# CY8C5888LTI_LP097 register map
File version: 0.1
CY8C58LP
Registers are 8-bit, read-write, no defined reset value unless marked. A register's access mark holds for its fields unless they carry their own. Offsets are from the block's base; lines under a group give offsets from that group; [hi:lo] are bit positions; {n}, {i} and the like mark numbered series; 'fields as' and 'values as' point back to an identical list; <NAME> marks a mode.

## Memory map
0x00000000 ADC_SAR_2 — SAR ADC
0x00000000 SPIS_1
0x00000000 Timer_1
0x00000000 ADC_SAR_1 — SAR ADC
0x00000000 UART_1 — UART

## ADC_SAR_2 — SAR ADC
Base 0x00000000
0x40004614 SAR_TR0 — SAR trim register
{0x40005900+i} SAR_CSR{i} (i=0..6) — SAR status and control register {i}
0x40005B20 SAR_SW0 — SAR Analog Routing Register 0
{0x40005B20+i} SAR_SW{i} (i=2..4) — SAR Analog Routing Register {i}
0x40005B26 SAR_SW6 — SAR Analog Routing Register 6
0x40005B27 SAR_CLK — SAR Clock Selection Register
0x40005BA0 SAR_WRK 16-bit — SAR working register

## SPIS_1
Base 0x00000000
0x4000640A SPIS_1_TX_DATA — SPIS TX Data
0x4000640A SPIS_1_RX_DATA — SPIS RX Data
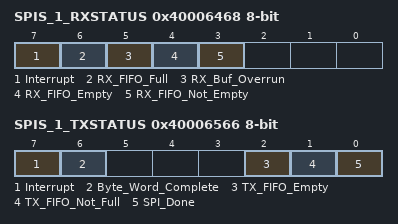
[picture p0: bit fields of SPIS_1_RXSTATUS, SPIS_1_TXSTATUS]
0x40006468 SPIS_1_RXSTATUS — SPIS RX Status Register
  [7] Interrupt ro — Set when interrupt occurs
  [6] RX_FIFO_Full ro — Set when the RX Data FIFO is full
  [5] RX_Buf_Overrun ro — Set when RX Data has overrun the 4 byte/word FIFO without being moved to the RX buffer cmemory array (if one exists)
  [4] RX_FIFO_Empty ro — Set when the RX Data FIFO is empty
  [3] RX_FIFO_Not_Empty ro — Set when the RX Data FIFO is not empty. That is, at least one byte/word is in the RX FIFO
0x40006566 SPIS_1_TXSTATUS — SPIS TX Status Register
  [7] Interrupt ro — Set when interrupt occurs
  [6] Byte_Word_Complete ro — Set when a byte/word transmit has completed
  [2] TX_FIFO_Empty ro — Set when the TX Data FIFO is empty
  [1] TX_FIFO_Not_Full ro — Set when the TX Data FIFO is not full
  [0] SPI_Done ro — Set when all of the data in the transmit FIFO has been sent. Set when Byte/Word Complete has been set and TX Data FIFO is empty

## Timer_1
Base 0x00000000
0x40006504 Timer_1_COUNTER 32-bit — UDB.A0 - Current Down Counter Value
0x40006524 Timer_1_PERIOD 32-bit — UDB.D0 - Assigned Period
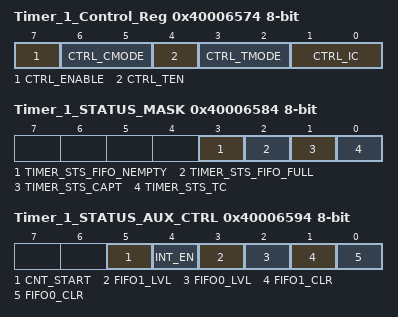
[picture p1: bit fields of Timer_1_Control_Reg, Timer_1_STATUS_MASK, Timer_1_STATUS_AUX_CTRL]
0x40006574 Timer_1_Control_Reg — UDB Control Register - Assigned Control Register Value
  [7] CTRL_ENABLE — Enable the Timer
  [6:5] CTRL_CMODE — Capture Mode
  [4] CTRL_TEN — Trigger Enable Bit
  [3:2] CTRL_TMODE — Trigger Mode
  [1:0] CTRL_IC — Interrupt Count
0x40006584 Timer_1_STATUS_MASK — UDB Status bits Interrupt Mask Enable Register
  [3] TIMER_STS_FIFO_NEMPTY ro — FIFO Empty status
  [2] TIMER_STS_FIFO_FULL ro — FIFO Full Status
  [1] TIMER_STS_CAPT ro — Enables the Interrupt on Capture
  [0] TIMER_STS_TC ro — Enables the Interrupt on TC
0x40006594 Timer_1_STATUS_AUX_CTRL — UDB Auxilliary Control Register
  [5] CNT_START — FIFO0 clear
    0=E_CNT_START0 (Disable counter); 1=E_CNT_START1 (Enable counter)
  [4] INT_EN
    0=E_INT_EN0 (Interrupt disabled); 1=E_INT_EN1 (Interrupt enabled)
  [3] FIFO1_LVL — FIFO level
    0=E_FIFO_LVL_0 (FIFO LVL: input mode: FIFO not full; output mode: FIFO not empty); 1=E_FIFO_LVL_1 (FIFO LVL: input mode: FIFO at least 1/2 empty; output mode: FIFO at least 1/2 full)
  [2] FIFO0_LVL — FIFO level
    values as FIFO1_LVL
  [1] FIFO1_CLR — FIFO1 clear
    0=E_FIFO_CLR_0 (Normal FIFO operation); 1=E_FIFO_CLR_1 (Clear FIFO state)
  [0] FIFO0_CLR — FIFO0 clear
    values as FIFO1_CLR

## ADC_SAR_1 — SAR ADC
Base 0x00000000
0x40004616 SAR_TR0 — SAR trim register
{0x40005908+i} SAR_CSR{i} (i=0..6) — SAR status and control register {i}
0x40005B28 SAR_SW0 — SAR Analog Routing Register 0
{0x40005B28+i} SAR_SW{i} (i=2..4) — SAR Analog Routing Register {i}
0x40005B2E SAR_SW6 — SAR Analog Routing Register 6
0x40005B2F SAR_CLK — SAR Clock Selection Register
0x40005BA2 SAR_WRK 16-bit — SAR working register

## UART_1 — UART
Base 0x00000000
0x40006449 TX_UART_1_TX_DATA — TX Data Register
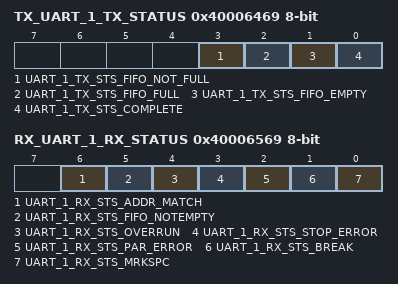
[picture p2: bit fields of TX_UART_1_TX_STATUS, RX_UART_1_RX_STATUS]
0x40006469 TX_UART_1_TX_STATUS — TX status register
  [3] UART_1_TX_STS_FIFO_NOT_FULL ro, [2] UART_1_TX_STS_FIFO_FULL ro, [1] UART_1_TX_STS_FIFO_EMPTY ro, [0] UART_1_TX_STS_COMPLETE ro
0x4000652A RX_UART_1_RX_ADDRESS1 — RX Address1 Register
0x4000653A RX_UART_1_RX_ADDRESS2 — RX Address2 Register
0x4000654A RX_UART_1_RX_DATA — RX Data Register
0x40006569 RX_UART_1_RX_STATUS — RX status register
  [6] UART_1_RX_STS_ADDR_MATCH ro, [5] UART_1_RX_STS_FIFO_NOTEMPTY ro, [4] UART_1_RX_STS_OVERRUN ro, [3] UART_1_RX_STS_STOP_ERROR ro, [2] UART_1_RX_STS_PAR_ERROR ro, [1] UART_1_RX_STS_BREAK ro, [0] UART_1_RX_STS_MRKSPC ro
